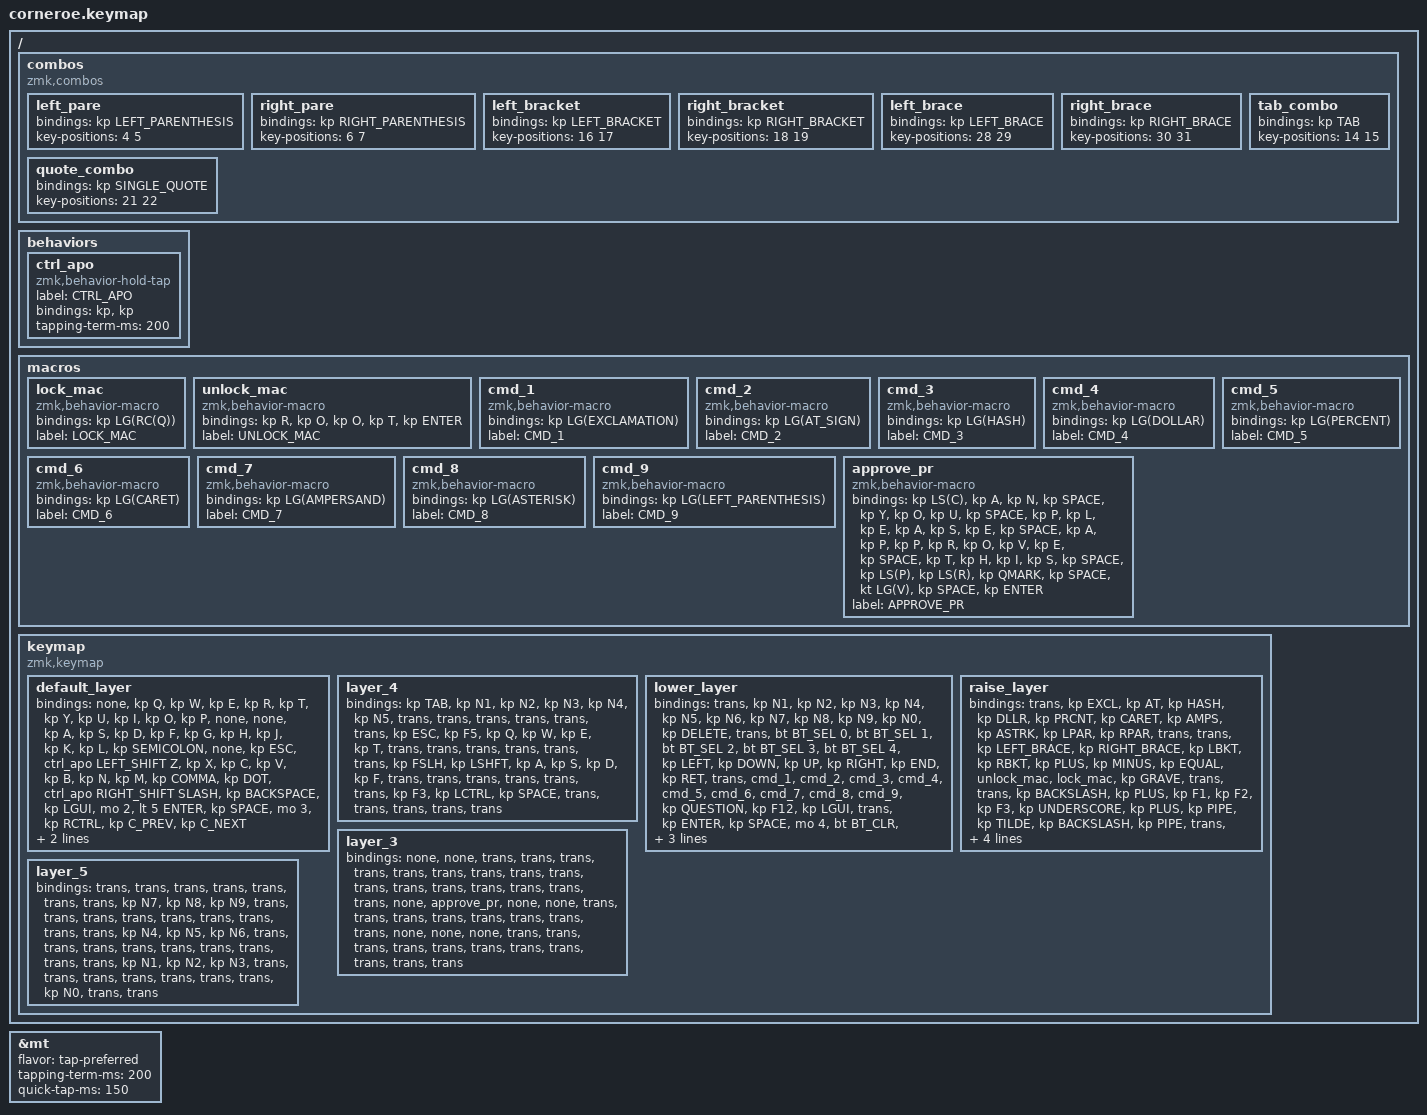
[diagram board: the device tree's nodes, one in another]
/*
 * Copyright (c) 2020 The ZMK Contributors
 *
 * SPDX-License-Identifier: MIT
 */

#include <dt-bindings/zmk/mouse.h>
#include <behaviors.dtsi>
#include <dt-bindings/zmk/bt.h>
#include <dt-bindings/zmk/keys.h>

&mt {
    flavor = "tap-preferred";
    tapping-term-ms = <200>;
    quick-tap-ms = <150>;
};

/ {
    combos {
        compatible = "zmk,combos";

        left_pare {
            bindings = <&kp LEFT_PARENTHESIS>;
            key-positions = <4 5>;
        };

        right_pare {
            bindings = <&kp RIGHT_PARENTHESIS>;
            key-positions = <6 7>;
        };

        left_bracket {
            bindings = <&kp LEFT_BRACKET>;
            key-positions = <16 17>;
        };

        right_bracket {
            bindings = <&kp RIGHT_BRACKET>;
            key-positions = <18 19>;
        };

        left_brace {
            bindings = <&kp LEFT_BRACE>;
            key-positions = <28 29>;
        };

        right_brace {
            bindings = <&kp RIGHT_BRACE>;
            key-positions = <30 31>;
        };

        tab_combo {
            bindings = <&kp TAB>;
            key-positions = <14 15>;
        };

        quote_combo {
            bindings = <&kp SINGLE_QUOTE>;
            key-positions = <21 22>;
        };
    };

    behaviors {
        ctrl_apo: ctrl_apo {
            compatible = "zmk,behavior-hold-tap";
            label = "CTRL_APO";
            bindings = <&kp>, <&kp>;

            #binding-cells = <2>;
            tapping-term-ms = <200>;
        };
    };

    macros {
        lock_mac: lock_mac {
            compatible = "zmk,behavior-macro";
            #binding-cells = <0>;
            bindings = <&kp LG(RC(Q))>;
            label = "LOCK_MAC";
        };

        unlock_mac: unlock_mac {
            compatible = "zmk,behavior-macro";
            #binding-cells = <0>;
            bindings = <&kp R &kp O &kp O &kp T &kp ENTER>;
            label = "UNLOCK_MAC";
        };

        cmd_1: cmd_1 {
            compatible = "zmk,behavior-macro";
            #binding-cells = <0>;
            bindings = <&kp LG(EXCLAMATION)>;
            label = "CMD_1";
        };

        cmd_2: cmd_2 {
            compatible = "zmk,behavior-macro";
            #binding-cells = <0>;
            bindings = <&kp LG(AT_SIGN)>;
            label = "CMD_2";
        };

        cmd_3: cmd_3 {
            compatible = "zmk,behavior-macro";
            #binding-cells = <0>;
            bindings = <&kp LG(HASH)>;
            label = "CMD_3";
        };

        cmd_4: cmd_4 {
            compatible = "zmk,behavior-macro";
            #binding-cells = <0>;
            bindings = <&kp LG(DOLLAR)>;
            label = "CMD_4";
        };

        cmd_5: cmd_5 {
            compatible = "zmk,behavior-macro";
            #binding-cells = <0>;
            bindings = <&kp LG(PERCENT)>;
            label = "CMD_5";
        };

        cmd_6: cmd_6 {
            compatible = "zmk,behavior-macro";
            #binding-cells = <0>;
            bindings = <&kp LG(CARET)>;
            label = "CMD_6";
        };

        cmd_7: cmd_7 {
            compatible = "zmk,behavior-macro";
            #binding-cells = <0>;
            bindings = <&kp LG(AMPERSAND)>;
            label = "CMD_7";
        };

        cmd_8: cmd_8 {
            compatible = "zmk,behavior-macro";
            #binding-cells = <0>;
            bindings = <&kp LG(ASTERISK)>;
            label = "CMD_8";
        };

        cmd_9: cmd_9 {
            compatible = "zmk,behavior-macro";
            #binding-cells = <0>;
            bindings = <&kp LG(LEFT_PARENTHESIS)>;
            label = "CMD_9";
        };

        approve_pr: approve_pr {
            compatible = "zmk,behavior-macro";
            #binding-cells = <0>;
            bindings = <&kp LS(C) &kp A &kp N &kp SPACE &kp Y &kp O &kp U &kp SPACE &kp P &kp L &kp E &kp A &kp S &kp E &kp SPACE &kp A &kp P &kp P &kp R &kp O &kp V &kp E &kp SPACE &kp T &kp H &kp I &kp S &kp SPACE &kp LS(P) &kp LS(R) &kp QMARK &kp SPACE &kt LG(V) &kp SPACE &kp ENTER>;
            label = "APPROVE_PR";
        };
    };

    keymap {
        compatible = "zmk,keymap";

        default_layer {
            // -----------------------------------------------------------------------------------------
            // |  TAB |  Q  |  W  |  E  |  R  |  T  |   |  Y  |  U   |  I  |  O  |  P  | BSPC |
            // | CTRL |  A  |  S  |  D  |  F  |  G  |   |  H  |  J   |  K  |  L  |  ;  |  '   |
            // | SHFT |  Z  |  X  |  C  |  V  |  B  |   |  N  |  M   |  ,  |  .  |  /  | ESC  |
            //                    | GUI | LWR | SPC |   | ENT | RSE  | ALT |

            bindings = <
&none  &kp Q  &kp W  &kp E  &kp R  &kp T  &kp Y  &kp U  &kp I  &kp O  &kp P  &none  &none  &kp A  &kp S  &kp D  &kp F  &kp G  &kp H  &kp J  &kp K  &kp L  &kp SEMICOLON  &none  &kp ESC  &ctrl_apo LEFT_SHIFT Z  &kp X  &kp C  &kp V  &kp B  &kp N  &kp M  &kp COMMA  &kp DOT  &ctrl_apo RIGHT_SHIFT SLASH  &kp BACKSPACE  &kp LGUI  &mo 2  &lt 5 ENTER  &kp SPACE  &mo 3  &kp RCTRL  &kp C_PREV  &kp C_NEXT
            >;

            sensor-bindings = <&inc_dec_kp C_VOL_DN C_VOL_UP &inc_dec_kp PG_UP PG_DN>;
        };

        layer_4 {
            bindings = <
&kp TAB  &kp N1  &kp N2  &kp N3  &kp N4  &kp N5  &trans  &trans  &trans  &trans  &trans  &trans  &kp ESC  &kp F5  &kp Q  &kp W  &kp E  &kp T  &trans  &trans  &trans  &trans  &trans  &trans  &kp FSLH  &kp LSHFT  &kp A  &kp S  &kp D  &kp F  &trans  &trans  &trans  &trans  &trans  &trans  &kp F3  &kp LCTRL  &kp SPACE  &trans  &trans  &trans  &trans  &trans
            >;
        };

        lower_layer {
            // -----------------------------------------------------------------------------------------
            // |  TAB |  1  |  2  |  3  |  4  |  5  |   |  6  |  7  |  8  |  9  |  0  | BSPC |
            // | BTCLR| BT1 | BT2 | BT3 | BT4 | BT5 |   | LFT | DWN |  UP | RGT |     |      |
            // | SHFT |     |     |     |     |     |   |     |     |     |     |     |      |
            //                    | GUI |     | SPC |   | ENT |     | ALT |

            bindings = <
&trans  &kp N1  &kp N2  &kp N3  &kp N4  &kp N5  &kp N6  &kp N7  &kp N8  &kp N9  &kp N0  &kp DELETE  &trans  &bt BT_SEL 0  &bt BT_SEL 1  &bt BT_SEL 2  &bt BT_SEL 3  &bt BT_SEL 4  &kp LEFT  &kp DOWN  &kp UP  &kp RIGHT  &kp END  &kp RET  &trans  &cmd_1  &cmd_2  &cmd_3  &cmd_4  &cmd_5  &cmd_6  &cmd_7  &cmd_8  &cmd_9  &kp QUESTION  &kp F12  &kp LGUI  &trans  &kp ENTER  &kp SPACE  &mo 4  &bt BT_CLR  &kp C_PLAY_PAUSE  &trans
            >;

            sensor-bindings = <&inc_dec_kp C_VOL_UP C_VOL_DN &inc_dec_kp PG_UP PG_DN>;
        };

        raise_layer {
            // -----------------------------------------------------------------------------------------
            // |  TAB |  !  |  @  |  #  |  $  |  %  |   |  ^  |  &  |  *  |  (  |  )  | BSPC |
            // | CTRL |     |     |     |     |     |   |  -  |  =  |  [  |  ]  |  \  |  `   |
            // | SHFT |     |     |     |     |     |   |  _  |  +  |  {  |  }  | "|" |  ~   |
            //                    | GUI |     | SPC |   | ENT |     | ALT |

            bindings = <
&trans  &kp EXCL  &kp AT  &kp HASH  &kp DLLR  &kp PRCNT  &kp CARET  &kp AMPS  &kp ASTRK  &kp LPAR  &kp RPAR  &trans  &trans  &kp LEFT_BRACE  &kp RIGHT_BRACE  &kp LBKT  &kp RBKT  &kp PLUS  &kp MINUS  &kp EQUAL  &unlock_mac  &lock_mac  &kp GRAVE  &trans  &trans  &kp BACKSLASH  &kp PLUS  &kp F1  &kp F2  &kp F3  &kp UNDERSCORE  &kp PLUS  &kp PIPE  &kp TILDE  &kp BACKSLASH  &kp PIPE  &trans  &trans  &kp LEFT_SHIFT  &kp LEFT_CONTROL  &trans  &kp RALT  &tog 1  &trans
            >;

            sensor-bindings = <&inc_dec_kp C_VOL_UP C_VOL_DN &inc_dec_kp PG_UP PG_DN>;
        };

        layer_3 {
            bindings = <
&none  &none  &trans  &trans  &trans  &trans  &trans  &trans  &trans  &trans  &trans  &trans  &trans  &trans  &trans  &trans  &trans  &trans  &none  &approve_pr  &none  &none  &trans  &trans  &trans  &trans  &trans  &trans  &trans  &trans  &none  &none  &none  &trans  &trans  &trans  &trans  &trans  &trans  &trans  &trans  &trans  &trans  &trans
            >;
        };

        layer_5 {
            bindings = <
&trans  &trans  &trans  &trans  &trans  &trans  &trans  &kp N7  &kp N8  &kp N9  &trans  &trans  &trans  &trans  &trans  &trans  &trans  &trans  &trans  &kp N4  &kp N5  &kp N6  &trans  &trans  &trans  &trans  &trans  &trans  &trans  &trans  &trans  &kp N1  &kp N2  &kp N3  &trans  &trans  &trans  &trans  &trans  &trans  &trans  &kp N0  &trans  &trans
            >;
        };
    };
};
